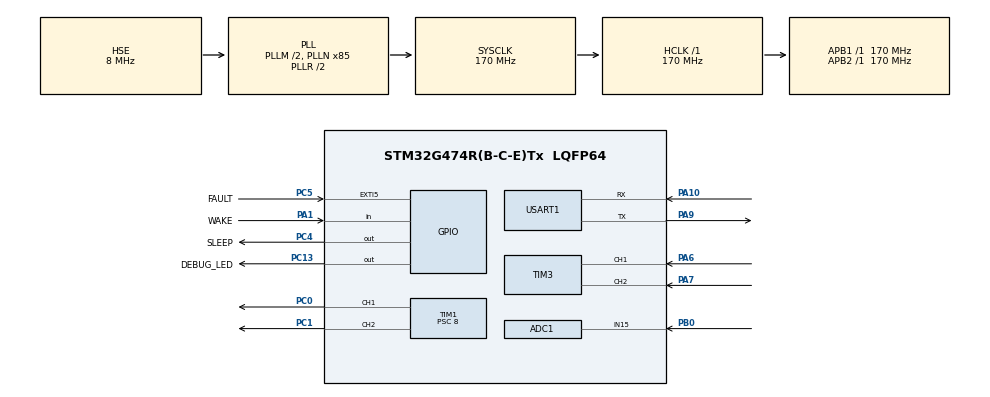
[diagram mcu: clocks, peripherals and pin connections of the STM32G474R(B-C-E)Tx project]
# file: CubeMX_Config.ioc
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ADC1.Channel-1\#ChannelRegularConversion=ADC_CHANNEL_15
ADC1.ContinuousConvMode=ENABLE
ADC1.DMAContinuousRequests=ENABLE
ADC1.GainCompensation=0
ADC1.NbrOfConversionFlag=1
ADC1.OffsetNumber-1\#ChannelRegularConversion=ADC_OFFSET_NONE
ADC1.Rank-1\#ChannelRegularConversion=1
ADC1.SamplingTime-1\#ChannelRegularConversion=ADC_SAMPLETIME_47CYCLES_5
ADC1.master=1
Dma.ADC1.1.Direction=DMA_PERIPH_TO_MEMORY
Dma.ADC1.1.EventEnable=DISABLE
Dma.ADC1.1.Instance=DMA1_Channel7
Dma.ADC1.1.MemDataAlignment=DMA_MDATAALIGN_HALFWORD
Dma.ADC1.1.MemInc=DMA_MINC_ENABLE
Dma.ADC1.1.Mode=DMA_CIRCULAR
Dma.ADC1.1.PeriphDataAlignment=DMA_PDATAALIGN_HALFWORD
Dma.ADC1.1.PeriphInc=DMA_PINC_DISABLE
Dma.ADC1.1.Polarity=HAL_DMAMUX_REQ_GEN_RISING
Dma.ADC1.1.Priority=DMA_PRIORITY_LOW
Dma.ADC1.1.RequestNumber=1
Dma.ADC1.1.SignalID=NONE
Dma.ADC1.1.SyncEnable=DISABLE
Dma.ADC1.1.SyncPolarity=HAL_DMAMUX_SYNC_NO_EVENT
Dma.ADC1.1.SyncRequestNumber=1
Dma.ADC1.1.SyncSignalID=NONE
Dma.Request0=USART1_TX
Dma.Request1=ADC1
Dma.USART1_TX.0.Direction=DMA_MEMORY_TO_PERIPH
Dma.USART1_TX.0.EventEnable=DISABLE
Dma.USART1_TX.0.Instance=DMA1_Channel1
Dma.USART1_TX.0.MemDataAlignment=DMA_MDATAALIGN_BYTE
Dma.USART1_TX.0.MemInc=DMA_MINC_ENABLE
Dma.USART1_TX.0.Mode=DMA_NORMAL
Dma.USART1_TX.0.PeriphDataAlignment=DMA_PDATAALIGN_BYTE
Dma.USART1_TX.0.PeriphInc=DMA_PINC_DISABLE
Dma.USART1_TX.0.Polarity=HAL_DMAMUX_REQ_GEN_RISING
Dma.USART1_TX.0.Priority=DMA_PRIORITY_LOW
Dma.USART1_TX.0.RequestNumber=1
Dma.USART1_TX.0.SignalID=NONE
Dma.USART1_TX.0.SyncEnable=DISABLE
Dma.USART1_TX.0.SyncPolarity=HAL_DMAMUX_SYNC_NO_EVENT
Dma.USART1_TX.0.SyncRequestNumber=1
Dma.USART1_TX.0.SyncSignalID=NONE
Mcu.Family=STM32G4
Mcu.Name=STM32G474R(B-C-E)Tx
Mcu.Package=LQFP64
NVIC.DMA1_Channel1_IRQn=true\:0\:0\:false\:false\:true\:false\:true\:true
NVIC.DMA1_Channel7_IRQn=true\:0\:0\:false\:false\:true\:false\:true\:true
NVIC.EXTI9_5_IRQn=true\:0\:0\:false\:false\:true\:true\:true\:true
NVIC.PriorityGroup=NVIC_PRIORITYGROUP_4
NVIC.USART1_IRQn=true\:15\:0\:true\:false\:true\:true\:true\:true
PA1.GPIO_Label=WAKE
PA1.GPIO_PuPd=GPIO_PULLDOWN
PA1.Signal=GPIO_Input
PA10.Mode=Asynchronous
PA10.Signal=USART1_RX
PA13.Mode=Serial_Wire
PA13.Signal=SYS_JTMS-SWDIO
PA14.Mode=Serial_Wire
PA14.Signal=SYS_JTCK-SWCLK
PA6.Signal=S_TIM3_CH1
PA7.Signal=S_TIM3_CH2
PA9.Mode=Asynchronous
PA9.Signal=USART1_TX
PB0.Signal=SharedAnalog_PB0
PC0.Signal=S_TIM1_CH1
PC1.Signal=S_TIM1_CH2
PC13.GPIO_Label=DEBUG_LED
PC13.Signal=GPIO_Output
PC14-OSC32_IN.Mode=LSE-External-Oscillator
PC14-OSC32_IN.Signal=RCC_OSC32_IN
PC15-OSC32_OUT.Mode=LSE-External-Oscillator
PC15-OSC32_OUT.Signal=RCC_OSC32_OUT
PC4.GPIO_Label=SLEEP
PC4.GPIO_Speed=GPIO_SPEED_FREQ_VERY_HIGH
PC4.Signal=GPIO_Output
PC5.GPIO_Label=FAULT
PC5.GPIO_ModeDefaultEXTI=GPIO_MODE_IT_FALLING
PC5.GPIO_PuPd=GPIO_PULLUP
PC5.Signal=GPXTI5
PF0-OSC_IN.Mode=HSE-External-Oscillator
PF0-OSC_IN.Signal=RCC_OSC_IN
PF1-OSC_OUT.Mode=HSE-External-Oscillator
PF1-OSC_OUT.Signal=RCC_OSC_OUT
ProjectManager.HeapSize=0x200
ProjectManager.StackSize=0x400
ProjectManager.TargetToolchain=MDK-ARM V5.32
RCC.ADC12Freq_Value=170000000
RCC.ADC345Freq_Value=170000000
RCC.AHBFreq_Value=170000000
RCC.APB1Freq_Value=170000000
RCC.APB1TimFreq_Value=170000000
RCC.APB2Freq_Value=170000000
RCC.APB2TimFreq_Value=170000000
RCC.CortexFreq_Value=170000000
RCC.EXTERNAL_CLOCK_VALUE=12288000
RCC.HCLKFreq_Value=170000000
RCC.HSE_VALUE=8000000
RCC.HSI48_VALUE=48000000
RCC.HSI_VALUE=16000000
RCC.PLLM=RCC_PLLM_DIV2
RCC.PLLN=85
RCC.PLLSourceVirtual=RCC_PLLSOURCE_HSE
RCC.SYSCLKFreq_VALUE=170000000
RCC.SYSCLKSource=RCC_SYSCLKSOURCE_PLLCLK
RCC.USBFreq_Value=170000000
RCC.VCOOutputFreq_Value=340000000
SH.S_TIM1_CH1.0=TIM1_CH1,PWM Generation1 CH1
SH.S_TIM1_CH2.0=TIM1_CH2,PWM Generation2 CH2
SH.S_TIM3_CH1.0=TIM3_CH1,Encoder_Interface
SH.S_TIM3_CH2.0=TIM3_CH2,Encoder_Interface
SH.SharedAnalog_PB0.0=GPIO_Analog
SH.SharedAnalog_PB0.1=ADC1_IN15,IN15-Single-Ended
TIM1.Channel-PWM\ Generation1\ CH1=TIM_CHANNEL_1
TIM1.Channel-PWM\ Generation2\ CH2=TIM_CHANNEL_2
TIM1.PeriodNoDither=1000-1
TIM1.Prescaler=8
USART1.VirtualMode-Asynchronous=VM_ASYNC
VP_SYS_VS_DBSignals.Mode=DisableDeadBatterySignals
VP_SYS_V_VREFBUF.Mode=ExternalMode
VP_TIM1_VS_ClockSourceINT.Mode=Internal
VP_TIM7_VS_ClockSourceINT.Mode=Enable_Timer
board=custom

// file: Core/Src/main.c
/* USER CODE BEGIN Header */
/**
  ******************************************************************************
  * @file           : main.c
  * @brief          : Main program body
  ******************************************************************************
  * @attention
  *
  * Copyright (c) 2025 STMicroelectronics.
  * All rights reserved.
  *
  * This software is licensed under terms that can be found in the LICENSE file
  * in the root directory of this software component.
  * If no LICENSE file comes with this software, it is provided AS-IS.
  *
  ******************************************************************************
  */
/* USER CODE END Header */
#include "main.h"
#include "adc.h"
#include "dma.h"
#include "tim.h"
#include "usart.h"
#include "gpio.h"

/* USER CODE BEGIN Includes */
#include "log.h"
#include "delay.h"
#include "drv_8876.h"
/* USER CODE END Includes */

/* USER CODE BEGIN PV */
float motor_current = 0.000f;
/* USER CODE END PV */

void SystemClock_Config(void);

int main(void)
{

  /* MCU Configuration--------------------------------------------------------*/

  /* Reset of all peripherals, Initializes the Flash interface and the Systick. */
  HAL_Init();

  /* Configure the system clock */
  SystemClock_Config();

  /* Initialize all configured peripherals */
  MX_GPIO_Init();
  MX_DMA_Init();
  MX_USART1_UART_Init();
  MX_TIM1_Init();
  MX_TIM3_Init();
  MX_TIM7_Init();
  MX_ADC1_Init();
  /* USER CODE BEGIN 2 */
	DelayTimer_GlobalInit();
	log_init();
	drv8876_init();
//	Set_PWM_Duty(791);

	Set_PWM_Duty(620);
  /* USER CODE END 2 */

  /* Infinite loop */
  /* USER CODE BEGIN WHILE */
  while (1)
  {
		hal_led_star();
//		fault_process();
//		HAL_Delay(1000);
    /* USER CODE END WHILE */

  }
}

void SystemClock_Config(void)
{
  RCC_OscInitTypeDef RCC_OscInitStruct = {0};
  RCC_ClkInitTypeDef RCC_ClkInitStruct = {0};

  /** Configure the main internal regulator output voltage
  */
  HAL_PWREx_ControlVoltageScaling(PWR_REGULATOR_VOLTAGE_SCALE1_BOOST);

  /** Initializes the RCC Oscillators according to the specified parameters
  * in the RCC_OscInitTypeDef structure.
  */
  RCC_OscInitStruct.OscillatorType = RCC_OSCILLATORTYPE_HSE;
  RCC_OscInitStruct.HSEState = RCC_HSE_ON;
  RCC_OscInitStruct.PLL.PLLState = RCC_PLL_ON;
  RCC_OscInitStruct.PLL.PLLSource = RCC_PLLSOURCE_HSE;
  RCC_OscInitStruct.PLL.PLLM = RCC_PLLM_DIV2;
  RCC_OscInitStruct.PLL.PLLN = 85;
  RCC_OscInitStruct.PLL.PLLP = RCC_PLLP_DIV2;
  RCC_OscInitStruct.PLL.PLLQ = RCC_PLLQ_DIV2;
  RCC_OscInitStruct.PLL.PLLR = RCC_PLLR_DIV2;
  if (HAL_RCC_OscConfig(&RCC_OscInitStruct) != HAL_OK)
  {
    Error_Handler();
  }

  /** Initializes the CPU, AHB and APB buses clocks
  */
  RCC_ClkInitStruct.ClockType = RCC_CLOCKTYPE_HCLK|RCC_CLOCKTYPE_SYSCLK
                              |RCC_CLOCKTYPE_PCLK1|RCC_CLOCKTYPE_PCLK2;
  RCC_ClkInitStruct.SYSCLKSource = RCC_SYSCLKSOURCE_PLLCLK;
  RCC_ClkInitStruct.AHBCLKDivider = RCC_SYSCLK_DIV1;
  RCC_ClkInitStruct.APB1CLKDivider = RCC_HCLK_DIV1;
  RCC_ClkInitStruct.APB2CLKDivider = RCC_HCLK_DIV1;

  if (HAL_RCC_ClockConfig(&RCC_ClkInitStruct, FLASH_LATENCY_4) != HAL_OK)
  {
    Error_Handler();
  }
}

void Error_Handler(void)
{
  __disable_irq();
  while (1)
  {
  }
}
